VERSION ""

NS_ :

BS_:

BU_: SYNC_MCU CTRL_FL CTRL_FR CTRL_RL CTRL_RR

BO_ 2147483905 SET_CURRENT_FL: 4 SYNC_MCU
 SG_ current : 7|32@0- (0.001,0) [-200|200] "A" CTRL_FL

BO_ 2147484161 SET_CURRENT_BRAKE_FL: 4 SYNC_MCU
 SG_ current_brake : 7|32@0- (0.001,0) [0|200] "A" CTRL_FL

BO_ 2147484417 SET_RPM_FL: 4 SYNC_MCU
 SG_ erpm : 7|32@0- (1,0) [-200000|200000] "rpm" CTRL_FL

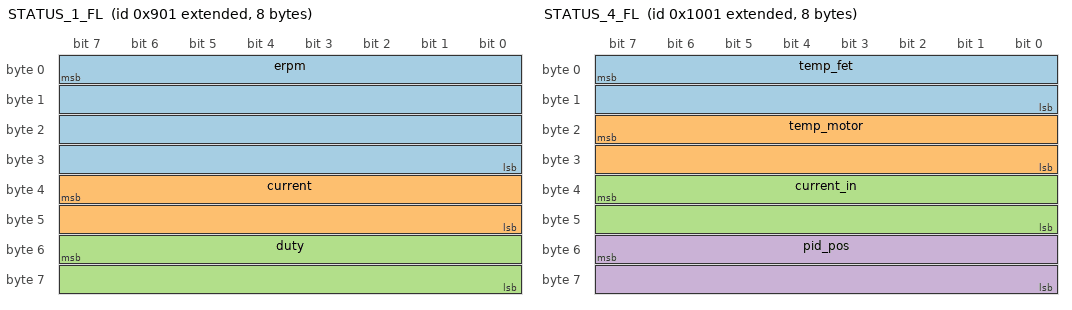
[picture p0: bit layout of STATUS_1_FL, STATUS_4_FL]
BO_ 2147485953 STATUS_1_FL: 8 CTRL_FL
 SG_ erpm : 7|32@0- (1,0) [-200000|200000] "rpm" SYNC_MCU
 SG_ current : 39|16@0- (0.1,0) [-3276.8|3276.7] "A" SYNC_MCU
 SG_ duty : 55|16@0- (0.001,0) [-1|1] "" SYNC_MCU

BO_ 2147487745 STATUS_4_FL: 8 CTRL_FL
 SG_ temp_fet : 7|16@0- (0.1,0) [-3276.8|3276.7] "degC" SYNC_MCU
 SG_ temp_motor : 23|16@0- (0.1,0) [-3276.8|3276.7] "degC" SYNC_MCU
 SG_ current_in : 39|16@0- (0.1,0) [-3276.8|3276.7] "A" SYNC_MCU
 SG_ pid_pos : 55|16@0- (0.02,0) [-655.36|655.34] "deg" SYNC_MCU

BO_ 2147490561 STATUS_5_FL: 8 CTRL_FL
 SG_ tachometer : 7|32@0- (1,0) [-2147483648|2147483647] "" SYNC_MCU
 SG_ voltage_in : 39|16@0- (0.1,0) [-3276.8|3276.7] "V" SYNC_MCU

BO_ 2147483906 SET_CURRENT_FR: 4 SYNC_MCU
 SG_ current : 7|32@0- (0.001,0) [-200|200] "A" CTRL_FR

BO_ 2147484162 SET_CURRENT_BRAKE_FR: 4 SYNC_MCU
 SG_ current_brake : 7|32@0- (0.001,0) [0|200] "A" CTRL_FR

BO_ 2147484418 SET_RPM_FR: 4 SYNC_MCU
 SG_ erpm : 7|32@0- (1,0) [-200000|200000] "rpm" CTRL_FR

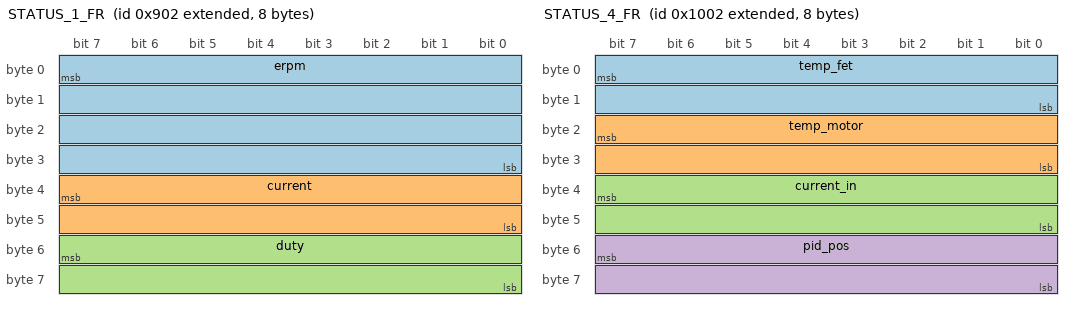
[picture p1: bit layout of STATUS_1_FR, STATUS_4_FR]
BO_ 2147485954 STATUS_1_FR: 8 CTRL_FR
 SG_ erpm : 7|32@0- (1,0) [-200000|200000] "rpm" SYNC_MCU
 SG_ current : 39|16@0- (0.1,0) [-3276.8|3276.7] "A" SYNC_MCU
 SG_ duty : 55|16@0- (0.001,0) [-1|1] "" SYNC_MCU

BO_ 2147487746 STATUS_4_FR: 8 CTRL_FR
 SG_ temp_fet : 7|16@0- (0.1,0) [-3276.8|3276.7] "degC" SYNC_MCU
 SG_ temp_motor : 23|16@0- (0.1,0) [-3276.8|3276.7] "degC" SYNC_MCU
 SG_ current_in : 39|16@0- (0.1,0) [-3276.8|3276.7] "A" SYNC_MCU
 SG_ pid_pos : 55|16@0- (0.02,0) [-655.36|655.34] "deg" SYNC_MCU

BO_ 2147490562 STATUS_5_FR: 8 CTRL_FR
 SG_ tachometer : 7|32@0- (1,0) [-2147483648|2147483647] "" SYNC_MCU
 SG_ voltage_in : 39|16@0- (0.1,0) [-3276.8|3276.7] "V" SYNC_MCU

BO_ 2147483907 SET_CURRENT_RL: 4 SYNC_MCU
 SG_ current : 7|32@0- (0.001,0) [-200|200] "A" CTRL_RL

BO_ 2147484163 SET_CURRENT_BRAKE_RL: 4 SYNC_MCU
 SG_ current_brake : 7|32@0- (0.001,0) [0|200] "A" CTRL_RL

BO_ 2147484419 SET_RPM_RL: 4 SYNC_MCU
 SG_ erpm : 7|32@0- (1,0) [-200000|200000] "rpm" CTRL_RL

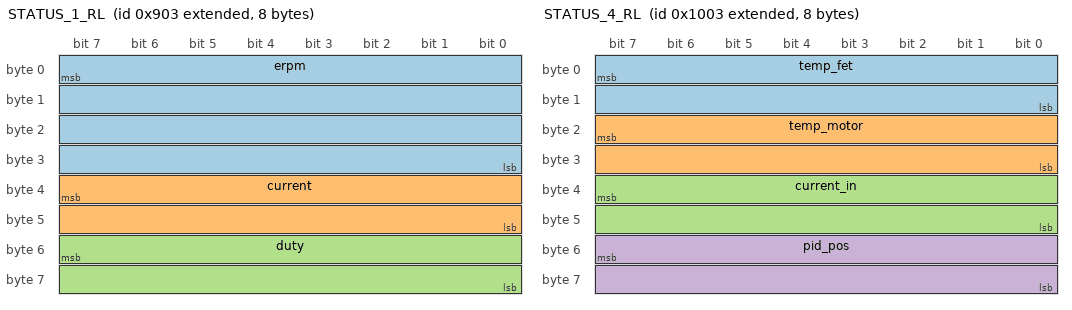
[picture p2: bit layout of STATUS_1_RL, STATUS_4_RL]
BO_ 2147485955 STATUS_1_RL: 8 CTRL_RL
 SG_ erpm : 7|32@0- (1,0) [-200000|200000] "rpm" SYNC_MCU
 SG_ current : 39|16@0- (0.1,0) [-3276.8|3276.7] "A" SYNC_MCU
 SG_ duty : 55|16@0- (0.001,0) [-1|1] "" SYNC_MCU

BO_ 2147487747 STATUS_4_RL: 8 CTRL_RL
 SG_ temp_fet : 7|16@0- (0.1,0) [-3276.8|3276.7] "degC" SYNC_MCU
 SG_ temp_motor : 23|16@0- (0.1,0) [-3276.8|3276.7] "degC" SYNC_MCU
 SG_ current_in : 39|16@0- (0.1,0) [-3276.8|3276.7] "A" SYNC_MCU
 SG_ pid_pos : 55|16@0- (0.02,0) [-655.36|655.34] "deg" SYNC_MCU

BO_ 2147490563 STATUS_5_RL: 8 CTRL_RL
 SG_ tachometer : 7|32@0- (1,0) [-2147483648|2147483647] "" SYNC_MCU
 SG_ voltage_in : 39|16@0- (0.1,0) [-3276.8|3276.7] "V" SYNC_MCU

BO_ 2147483908 SET_CURRENT_RR: 4 SYNC_MCU
 SG_ current : 7|32@0- (0.001,0) [-200|200] "A" CTRL_RR

BO_ 2147484164 SET_CURRENT_BRAKE_RR: 4 SYNC_MCU
 SG_ current_brake : 7|32@0- (0.001,0) [0|200] "A" CTRL_RR

BO_ 2147484420 SET_RPM_RR: 4 SYNC_MCU
 SG_ erpm : 7|32@0- (1,0) [-200000|200000] "rpm" CTRL_RR

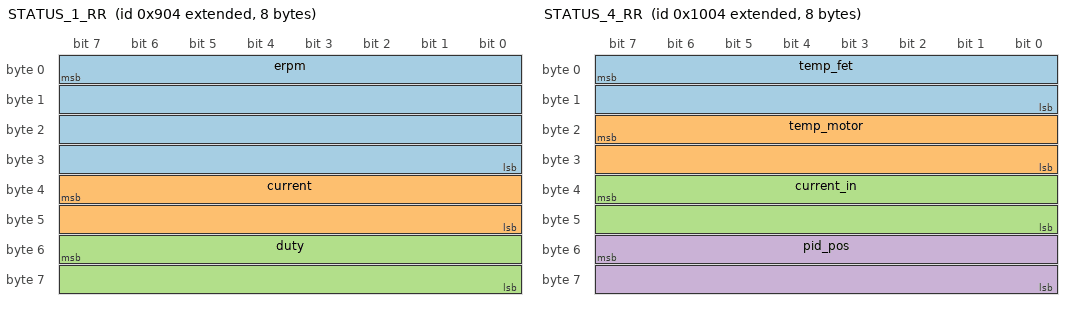
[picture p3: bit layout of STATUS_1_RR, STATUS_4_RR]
BO_ 2147485956 STATUS_1_RR: 8 CTRL_RR
 SG_ erpm : 7|32@0- (1,0) [-200000|200000] "rpm" SYNC_MCU
 SG_ current : 39|16@0- (0.1,0) [-3276.8|3276.7] "A" SYNC_MCU
 SG_ duty : 55|16@0- (0.001,0) [-1|1] "" SYNC_MCU

BO_ 2147487748 STATUS_4_RR: 8 CTRL_RR
 SG_ temp_fet : 7|16@0- (0.1,0) [-3276.8|3276.7] "degC" SYNC_MCU
 SG_ temp_motor : 23|16@0- (0.1,0) [-3276.8|3276.7] "degC" SYNC_MCU
 SG_ current_in : 39|16@0- (0.1,0) [-3276.8|3276.7] "A" SYNC_MCU
 SG_ pid_pos : 55|16@0- (0.02,0) [-655.36|655.34] "deg" SYNC_MCU

BO_ 2147490564 STATUS_5_RR: 8 CTRL_RR
 SG_ tachometer : 7|32@0- (1,0) [-2147483648|2147483647] "" SYNC_MCU
 SG_ voltage_in : 39|16@0- (0.1,0) [-3276.8|3276.7] "V" SYNC_MCU

CM_ "can-command: the classic CAN command bus between the sync MCU and the four motor controllers (ADR-0009, ADR-0034). Stock VESC frames from the vendored VESC firmware (release_7_00, comm/comm_can.c): extended IDs, big-endian. Controller IDs 1-4 = FL, FR, RL, RR (draft).";
CM_ BO_ 2147483905 "VESC CAN_PACKET_SET_CURRENT: motor current (torque) command. Extended ID = (1 << 8) | controller ID.";
CM_ BO_ 2147484161 "VESC CAN_PACKET_SET_CURRENT_BRAKE: braking current command.";
CM_ BO_ 2147484417 "VESC CAN_PACKET_SET_RPM: electrical speed command.";
CM_ BO_ 2147485953 "VESC CAN_PACKET_STATUS: health status on the command bus at a low rate; full telemetry goes over the UART (ICD-controller-telemetry).";
CM_ BO_ 2147487745 "VESC CAN_PACKET_STATUS_4: temperatures and input current.";
CM_ BO_ 2147490561 "VESC CAN_PACKET_STATUS_5: tachometer and input voltage; bytes 6-7 reserved.";
CM_ BO_ 2147483906 "VESC CAN_PACKET_SET_CURRENT: motor current (torque) command. Extended ID = (1 << 8) | controller ID.";
CM_ BO_ 2147484162 "VESC CAN_PACKET_SET_CURRENT_BRAKE: braking current command.";
CM_ BO_ 2147484418 "VESC CAN_PACKET_SET_RPM: electrical speed command.";
CM_ BO_ 2147485954 "VESC CAN_PACKET_STATUS: health status on the command bus at a low rate; full telemetry goes over the UART (ICD-controller-telemetry).";
CM_ BO_ 2147487746 "VESC CAN_PACKET_STATUS_4: temperatures and input current.";
CM_ BO_ 2147490562 "VESC CAN_PACKET_STATUS_5: tachometer and input voltage; bytes 6-7 reserved.";
CM_ BO_ 2147483907 "VESC CAN_PACKET_SET_CURRENT: motor current (torque) command. Extended ID = (1 << 8) | controller ID.";
CM_ BO_ 2147484163 "VESC CAN_PACKET_SET_CURRENT_BRAKE: braking current command.";
CM_ BO_ 2147484419 "VESC CAN_PACKET_SET_RPM: electrical speed command.";
CM_ BO_ 2147485955 "VESC CAN_PACKET_STATUS: health status on the command bus at a low rate; full telemetry goes over the UART (ICD-controller-telemetry).";
CM_ BO_ 2147487747 "VESC CAN_PACKET_STATUS_4: temperatures and input current.";
CM_ BO_ 2147490563 "VESC CAN_PACKET_STATUS_5: tachometer and input voltage; bytes 6-7 reserved.";
CM_ BO_ 2147483908 "VESC CAN_PACKET_SET_CURRENT: motor current (torque) command. Extended ID = (1 << 8) | controller ID.";
CM_ BO_ 2147484164 "VESC CAN_PACKET_SET_CURRENT_BRAKE: braking current command.";
CM_ BO_ 2147484420 "VESC CAN_PACKET_SET_RPM: electrical speed command.";
CM_ BO_ 2147485956 "VESC CAN_PACKET_STATUS: health status on the command bus at a low rate; full telemetry goes over the UART (ICD-controller-telemetry).";
CM_ BO_ 2147487748 "VESC CAN_PACKET_STATUS_4: temperatures and input current.";
CM_ BO_ 2147490564 "VESC CAN_PACKET_STATUS_5: tachometer and input voltage; bytes 6-7 reserved.";
